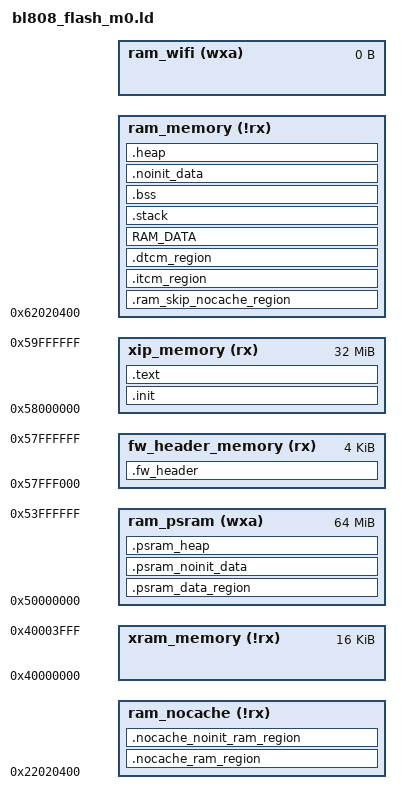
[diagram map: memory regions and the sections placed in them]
/****************************************************************************************
* @file flash.ld
*
* @brief This file is the link script file (gnuarm or armgcc).
*
* Copyright (C) BouffaloLab 2021
*
****************************************************************************************
*/

/* configure the CPU type */
OUTPUT_ARCH( "riscv" )

/* configure the entry point */
ENTRY(__start)

StackSize    = 0x0400; /*  1KB */
HeapMinSize  = 0x1000; /*  4KB */
psram_heap_min_size = 0x1000;
__EM_SIZE = DEFINED(btble_controller_init) ? 32K : 0K;
wifi_ram_max_size = 0K;

remain_wifi_ram = 160K - wifi_ram_max_size - __EM_SIZE;

MEMORY
{
    fw_header_memory  (rx)  : ORIGIN = 0x58000000 - 0x1000, LENGTH = 4K
    xip_memory  (rx)  : ORIGIN = 0x58000000, LENGTH = 32M
    ram_psram  (wxa)  : ORIGIN = 0x50000000, LENGTH = 64M
    ram_nocache (!rx) : ORIGIN = 0x22020400, LENGTH = 64K - 1K + remain_wifi_ram /* reserved 1k for security */
    ram_memory  (!rx) : ORIGIN = 0x62020400, LENGTH = 64K - 1K + remain_wifi_ram /* reserved 1k for security */
    ram_wifi  (wxa)   : ORIGIN = 0x23038000 - wifi_ram_max_size - __EM_SIZE, LENGTH = wifi_ram_max_size
    xram_memory  (!rx) : ORIGIN = 0x40000000, LENGTH = 16K
}

SECTIONS
{
    .fw_header :
    {
        KEEP(*(.fw_header))
    } > fw_header_memory

    .init :
    {
        KEEP (*(SORT_NONE(.init)))
        KEEP (*(SORT_NONE(.vector)))

    } > xip_memory

    .text :
    {
        . = ALIGN(4);
        __text_code_start__ = .;

        *(.text)
        *(.text.*)

        /* section information for shell */
        . = ALIGN(4);
        __fsymtab_start = .;
        KEEP(*(FSymTab))
        __fsymtab_end = .;

        . = ALIGN(4);
        __vsymtab_start = .;
        KEEP(*(VSymTab))
        __vsymtab_end = .;

        /* section information for usb usbh_class_info */
        . = ALIGN(4);
        __usbh_class_info_start__ = .;
        KEEP(*(.usbh_class_info))
        . = ALIGN(4);
        __usbh_class_info_end__ = .;

        /*put .rodata**/
        *(EXCLUDE_FILE( *bl808_glb*.o* \
                        *bl808_glb_gpio*.o* \
                        *bl808_pds*.o* \
                        *bl808_aon*.o* \
                        *bl808_hbn*.o* \
                        *bl808_l1c*.o* \
                        *bl808_common*.o* \
                        *bl808_clock*.o* \
                        *bl808_ef_ctrl*.o* \
                        *bl808_sf_cfg*.o* \
                        *bl808_sf_ctrl*.o* \
                        *bl808_sflash*.o* \
                        *bl808_xip_sflash*.o* \
                        *bl808_romapi_patch*.o* ) .rodata*)
        *(.srodata)
        *(.srodata.*)

        /* _dump_sections for bflb_coredump.c*/
        . = ALIGN(4);
        PROVIDE( _dump_sections = ABSOLUTE(.));
        LONG(ORIGIN(ram_memory));
        LONG(LENGTH(ram_memory));
        LONG(ORIGIN(ram_nocache));
        LONG(LENGTH(ram_nocache));
        LONG(ORIGIN(ram_wifi));
        LONG(LENGTH(ram_wifi));
        LONG(ORIGIN(xram_memory));
        LONG(LENGTH(xram_memory));
	/*
        LONG(ORIGIN(ram_psram));
        LONG(LENGTH(ram_psram));
         */
        LONG(0x28010000); /* bt memory */
        LONG(__EM_SIZE);
        LONG(0xffffffff);
        LONG(0xffffffff);
        /* _dump_sections for bl_coredump.c*/

        . = ALIGN(4);
        __text_code_end__ = .;
    } > xip_memory

    . = ALIGN(4);
    __nocache_ram_load_addr = .;

    .nocache_ram_region  : AT (__nocache_ram_load_addr)
    {
        . = ALIGN(4);
        __nocache_ram_data_start__ = .;

        *(.nocache_ram)

        . = ALIGN(4);
        __nocache_ram_data_end__ = .;
    } > ram_nocache

    .nocache_noinit_ram_region (NOLOAD) :
    {
        . = ALIGN(4);
        __nocache_noinit_ram_data_start__ = .;

        *(.nocache_noinit_ram)
        *(.noncacheable)

        . = ALIGN(4);
        __nocache_noinit_ram_data_end__ = .;
    } > ram_nocache

    /* Skip the nocache region */ 
    .ram_skip_nocache_region (NOLOAD) :
    {
        . += (__nocache_noinit_ram_data_end__ - ORIGIN(ram_nocache));
    } > ram_memory

    __itcm_load_addr = __nocache_ram_load_addr + SIZEOF(.nocache_ram_region);

    .itcm_region : AT (__itcm_load_addr)
    {
        . = ALIGN(4);
        __tcm_code_start__ = .;

        *(.tcm_code.*)
        *(.tcm_const.*)
        *(.sclock_rlt_code.*)
        *(.sclock_rlt_const.*)

        *bl808_glb*.o*(.rodata*)
        *bl808_glb_gpio*.o*(.rodata*)
        *bl808_pds*.o*(.rodata*)
        *bl808_aon*.o*(.rodata*)
        *bl808_hbn*.o*(.rodata*)
        *bl808_l1c*.o*(.rodata*)
        *bl808_common*.o*(.rodata*)
        *bl808_clock*.o*(.rodata*)
        *bl808_ef_ctrl*.o*(.rodata*)
        *bl808_sf_cfg*.o*(.rodata*)
        *bl808_sf_ctrl*.o*(.rodata*)
        *bl808_sflash*.o*(.rodata*)
        *bl808_xip_sflash*.o*(.rodata*)
        *bl808_romapi_patch*.o*(.rodata*)

        . = ALIGN(4);
        __tcm_code_end__ = .;
    } > ram_memory

    __dtcm_load_addr = __itcm_load_addr + SIZEOF(.itcm_region);

    .dtcm_region : AT (__dtcm_load_addr)
    {
        . = ALIGN(4);
        __tcm_data_start__ = .;

        *(.tcm_data)
        /* *finger_print.o(.data*) */

        . = ALIGN(4);
        __tcm_data_end__ = .;
    } > ram_memory

    __ram_load_addr = __dtcm_load_addr + SIZEOF(.nocache_ram_region);

    /* Data section */
    RAM_DATA : AT (__ram_load_addr)
    {
        . = ALIGN(4);
        __ram_data_start__ = .;

        PROVIDE( __global_pointer$ = . + 0x800 );

        *(.data)
        *(.data.*)
        *(.sdata)
        *(.sdata.*)
        *(.sdata2)
        *(.sdata2.*)

        . = ALIGN(8);
        *(._k_queue.static.*)
        *(._k_sem.static.*)
        *(._k_mutex.static.*)
        _bt_gatt_service_static_list_start = .;
        KEEP(*(SORT_BY_NAME("._bt_gatt_service_static.static.*")))
        _bt_gatt_service_static_list_end = .;
        _bt_l2cap_fixed_chan_list_start = .;
        KEEP(*(SORT_BY_NAME("._bt_l2cap_fixed_chan.static.*")))
        _bt_l2cap_fixed_chan_list_end = .;
        _bt_l2cap_br_fixed_chan_list_start = .;
        KEEP(*(SORT_BY_NAME("._bt_l2cap_br_fixed_chan.static.*")))
        _bt_l2cap_br_fixed_chan_list_end = .;

        . = ALIGN(4);
        __bflog_tags_start__ = .;
        *(.bflog_tags_array)
        . = ALIGN(4);
        __bflog_tags_end__ = .;
        __ram_data_end__ = .;
    } > ram_memory

    __psram_load_addr = (__ram_load_addr + SIZEOF (RAM_DATA));

    .psram_data_region : AT (__psram_load_addr)
    {
        . = ALIGN(4);
        __psram_data_start__ = .;

        KEEP(*(.psram_data*))

        . = ALIGN(4);
        __psram_data_end__ = .;
    } > ram_psram

    __etext_final = (__psram_load_addr + SIZEOF (.psram_data_region));
    ASSERT(__etext_final <= ORIGIN(xip_memory) + LENGTH(xip_memory), "code memory overflow")

    .stack (NOLOAD):
    {
        __StackLimit = .;
        . = ALIGN(16);
        . = . + StackSize;
        __StackTop = .;
        __freertos_irq_stack_top = .;
    } > ram_memory

    PROVIDE( __freertos_irq_stack_top = __StackTop);
    PROVIDE( _sp_main = __StackTop);
    PROVIDE( _sp_base = __StackLimit);

    .bss (NOLOAD) :
    {
        . = ALIGN(4);
        __bss_start__ = .;

        *(.bss*)
        *(.sbss*)
        *(COMMON)

        . = ALIGN(4);
        __bss_end__ = .;
    } > ram_memory

    .noinit_data (NOLOAD) :
    {
        . = ALIGN(4);
        __noinit_data_start__ = .;

        *(.noinit_data*)

        . = ALIGN(4);
        __noinit_data_end__ = .;
    } > ram_memory

    .heap (NOLOAD):
    {
        . = ALIGN(4);
        __HeapBase = .;

        /*__end__ = .;*/
        /*end = __end__;*/
        KEEP(*(.heap*))

        . = ALIGN(4);
        __HeapLimit = .;
    } > ram_memory

    __HeapLimit = ORIGIN(ram_memory) + LENGTH(ram_memory);
    ASSERT(__HeapLimit - __HeapBase >= HeapMinSize, "heap region overflow")

    .psram_noinit_data (NOLOAD):
    {
        . = ALIGN(4);
        __psram_noinit_data_start__ = .;

        KEEP(*(.psram_noinit*))

        . = ALIGN(4);
        __psram_noinit_data_end__ = .;
    } > ram_psram

    .psram_heap (NOLOAD):
    {
        . = ALIGN(4);
        __psram_heap_base = .;
        KEEP(*(.psram_heap*))
        . = ALIGN(4);
        __psram_heap_end = .;
    } > ram_psram

    __psram_limit = ORIGIN(ram_psram) + LENGTH(ram_psram);
    ASSERT(__psram_limit - __psram_heap_base >= psram_heap_min_size, "psram heap region overflow")
 
    PROVIDE(__LD_CONFIG_EM_SEL = __EM_SIZE);
}

